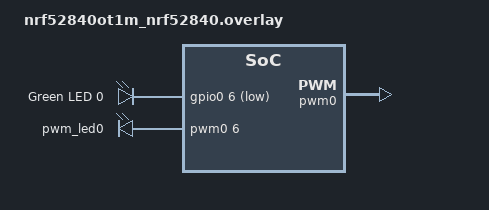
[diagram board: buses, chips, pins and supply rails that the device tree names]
/ {
    leds {
		compatible = "gpio-leds";
		led0: led_0 {
			gpios = <&gpio0 6 GPIO_ACTIVE_LOW>;
			label = "Green LED 0";
		};
	};
	pwmleds {
        compatible = "pwm-leds";
        pwm_led0: pwm_led_0 {
            pwms = <&pwm0 6>;
        };
    };
    aliases {
        pwm-led0 = &pwm_led0;
    };
};
&pwm0 {
	status = "okay";
	ch0-pin = <6>;
	ch0-inverted;
};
